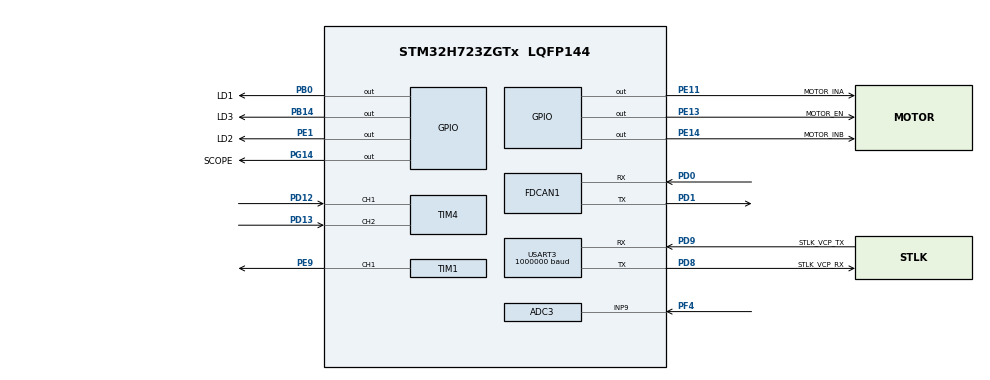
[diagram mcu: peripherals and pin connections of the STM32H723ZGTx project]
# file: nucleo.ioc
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ADC3.Channel-0\#ChannelRegularConversion=ADC_CHANNEL_9
ADC3.ClockPrescalerADC3=ADC_CLOCK_ASYNC_DIV8
ADC3.NbrOfConversionFlag=1
ADC3.OffsetNumber-0\#ChannelRegularConversion=ADC_OFFSET_NONE
ADC3.OffsetSign-0\#ChannelRegularConversion=ADC3_OFFSET_SIGN_NEGATIVE
ADC3.Rank-0\#ChannelRegularConversion=1
ADC3.SamplingTime-0\#ChannelRegularConversion=ADC3_SAMPLETIME_92CYCLES_5
CORTEX_M7.CPU_ICache=Enabled
CORTEX_M7.default_mode_Activation=1
FDCAN1.AutoRetransmission=ENABLE
FDCAN1.CalculateBaudRateNominal=1000000
FDCAN1.CalculateTimeBitNominal=1000
FDCAN1.CalculateTimeQuantumNominal=38.46153846153846
FDCAN1.Mode=FDCAN_MODE_NORMAL
FDCAN1.NominalPrescaler=5
FDCAN1.NominalSyncJumpWidth=5
FDCAN1.NominalTimeSeg1=20
FDCAN1.NominalTimeSeg2=5
FDCAN1.RxFifo0ElmtsNbr=16
FDCAN1.StdFiltersNbr=1
FDCAN1.TxFifoQueueElmtsNbr=16
FREERTOS.Tasks01=init,24,512,task_init,Default,NULL,Dynamic,NULL,NULL
FREERTOS.configCHECK_FOR_STACK_OVERFLOW=2
FREERTOS.configTOTAL_HEAP_SIZE=49152
FREERTOS.configUSE_NEWLIB_REENTRANT=1
Mcu.Family=STM32H7
Mcu.Name=STM32H723ZGTx
Mcu.Package=LQFP144
NVIC.FDCAN1_IT0_IRQn=true\:6\:0\:true\:false\:true\:true\:true\:true\:true
NVIC.PriorityGroup=NVIC_PRIORITYGROUP_4
NVIC.TIM17_IRQn=true\:15\:0\:false\:false\:true\:false\:false\:true\:true
NVIC.TIM6_DAC_IRQn=true\:4\:0\:true\:false\:true\:false\:true\:true\:true
NVIC.TimeBase=TIM17_IRQn
NVIC.TimeBaseIP=TIM17
NVIC.USART3_IRQn=true\:6\:0\:true\:false\:true\:true\:true\:true\:true
PA13(JTMS/SWDIO).GPIO_Label=SWDIO
PA13(JTMS/SWDIO).Mode=Serial_Wire
PA13(JTMS/SWDIO).Signal=DEBUG_JTMS-SWDIO
PA14(JTCK/SWCLK).GPIO_Label=SWCLK
PA14(JTCK/SWCLK).Mode=Serial_Wire
PA14(JTCK/SWCLK).Signal=DEBUG_JTCK-SWCLK
PB0.GPIO_Label=LD1
PB0.Signal=GPIO_Output
PB14.GPIO_Label=LD3
PB14.Signal=GPIO_Output
PC14-OSC32_IN.Signal=RCC_OSC32_IN
PC15-OSC32_OUT.Signal=RCC_OSC32_OUT
PD0.Mode=FDCAN_Activate
PD0.Signal=FDCAN1_RX
PD1.Mode=FDCAN_Activate
PD1.Signal=FDCAN1_TX
PD12.GPIO_PuPd=GPIO_PULLUP
PD12.Signal=S_TIM4_CH1
PD13.GPIO_PuPd=GPIO_PULLUP
PD13.Signal=S_TIM4_CH2
PD8.GPIO_Label=STLK_VCP_RX
PD8.Mode=Asynchronous
PD8.Signal=USART3_TX
PD9.GPIO_Label=STLK_VCP_TX
PD9.Mode=Asynchronous
PD9.Signal=USART3_RX
PE1.GPIO_Label=LD2
PE1.Signal=GPIO_Output
PE11.GPIO_Label=MOTOR_INA
PE11.Signal=GPIO_Output
PE13.GPIO_Label=MOTOR_EN
PE13.GPIO_ModeDefaultOutputPP=GPIO_MODE_OUTPUT_OD
PE13.GPIO_PuPd=GPIO_NOPULL
PE13.PinState=GPIO_PIN_SET
PE13.Signal=GPIO_Output
PE14.GPIO_Label=MOTOR_INB
PE14.Signal=GPIO_Output
PE9.Signal=S_TIM1_CH1
PF4.Mode=IN9-Single-Ended
PF4.Signal=ADC3_INP9
PG14.GPIO_Label=SCOPE
PG14.GPIO_Speed=GPIO_SPEED_FREQ_VERY_HIGH
PG14.Signal=GPIO_Output
PH0-OSC_IN.Mode=HSE-External-Clock-Source
PH0-OSC_IN.Signal=RCC_OSC_IN
ProjectManager.HeapSize=0x200
ProjectManager.StackSize=0x400
ProjectManager.TargetToolchain=CMake
RCC.ADCFreq_Value=96000000
RCC.APB1Freq_Value=130000000
RCC.APB2Freq_Value=130000000
RCC.APB3Freq_Value=130000000
RCC.APB4Freq_Value=130000000
RCC.CortexFreq_Value=520000000
RCC.D1PPRE=RCC_APB3_DIV2
RCC.D2PPRE1=RCC_APB1_DIV2
RCC.D2PPRE2=RCC_APB2_DIV2
RCC.D3PPRE=RCC_APB4_DIV2
RCC.DIVM1=1
RCC.DIVM2=1
RCC.DIVN1=104
RCC.DIVN2=96
RCC.DIVP1=1
RCC.DIVP2=5
RCC.DIVQ1=4
RCC.DIVQ2=5
RCC.HCLKFreq_Value=260000000
RCC.HPRE=RCC_HCLK_DIV2
RCC.HSE_VALUE=5000000
RCC.PLLFRACN=0
RCC.PLLSourceVirtual=RCC_PLLSOURCE_HSE
RCC.SYSCLKFreq_VALUE=520000000
RCC.SYSCLKSource=RCC_SYSCLKSOURCE_PLLCLK
RCC.USBCLockSelection=RCC_USBCLKSOURCE_HSI48
RCC.USBFreq_Value=48000000
SH.S_TIM1_CH1.0=TIM1_CH1,PWM Generation1 CH1
SH.S_TIM4_CH1.0=TIM4_CH1,Encoder_Interface
SH.S_TIM4_CH2.0=TIM4_CH2,Encoder_Interface
TIM1.AutoReloadPreload=TIM_AUTORELOAD_PRELOAD_ENABLE
TIM1.Channel-PWM\ Generation1\ CH1=TIM_CHANNEL_1
TIM1.Period=12999
TIM4.EncoderMode=TIM_ENCODERMODE_TI12
TIM4.IC1Filter=6
TIM4.IC1Polarity=TIM_ICPOLARITY_FALLING
TIM4.IC2Filter=6
TIM6.AutoReloadPreload=TIM_AUTORELOAD_PRELOAD_ENABLE
TIM6.Period=999
TIM6.Prescaler=259
USART3.BaudRate=1000000
USART3.VirtualMode-Asynchronous=VM_ASYNC
VP_FREERTOS_VS_CMSIS_V2.Mode=CMSIS_V2
VP_MEMORYMAP_VS_MEMORYMAP.Mode=CurAppReg
VP_SYS_VS_tim17.Mode=TIM17
VP_TIM1_VS_ClockSourceINT.Mode=Internal
VP_TIM6_VS_ClockSourceINT.Mode=Enable_Timer
board=NUCLEO-H723ZG

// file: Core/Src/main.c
/* USER CODE BEGIN Header */
/**
  ******************************************************************************
  * @file           : main.c
  * @brief          : Main program body
  ******************************************************************************
  * @attention
  *
  * Copyright (c) 2026 STMicroelectronics.
  * All rights reserved.
  *
  * This software is licensed under terms that can be found in the LICENSE file
  * in the root directory of this software component.
  * If no LICENSE file comes with this software, it is provided AS-IS.
  *
  ******************************************************************************
  */
/* USER CODE END Header */
#include "main.h"
#include "FreeRTOS.h"
#include "cmsis_os2.h"
#include "adc.h"
#include "fdcan.h"
#include "tim.h"
#include "usart.h"
#include "gpio.h"

/* USER CODE BEGIN Includes */
#include <stdio.h>
#include "version.h"
/* USER CODE END Includes */

void SystemClock_Config(void);
static void MPU_Config(void);
void MX_FREERTOS_Init(void);

int main(void)
{

  /* MPU Configuration--------------------------------------------------------*/
  MPU_Config();

  /* Enable the CPU Cache */

  /* Enable I-Cache---------------------------------------------------------*/
  SCB_EnableICache();

  /* MCU Configuration--------------------------------------------------------*/

  /* Reset of all peripherals, Initializes the Flash interface and the Systick. */
  HAL_Init();

  /* Configure the system clock */
  SystemClock_Config();

  /* Initialize all configured peripherals */
  MX_GPIO_Init();
  MX_TIM6_Init();
  MX_USART3_UART_Init();
  MX_FDCAN1_Init();
  MX_TIM1_Init();
  MX_TIM4_Init();
  MX_ADC3_Init();
  /* USER CODE BEGIN 2 */
  printf("| ---- BOOT %s (%s) %s ---- |\r\n", FW_VERSION_STR, FW_GIT_DESCRIBE, FW_BUILD_TYPE);
  /* USER CODE END 2 */

  /* Init scheduler */
  osKernelInitialize();  /* Call init function for freertos objects (in cmsis_os2.c) */
  MX_FREERTOS_Init();

  /* Start scheduler */
  osKernelStart();

  /* We should never get here as control is now taken by the scheduler */

  /* Infinite loop */
  while (1)
  {

  }
}

void SystemClock_Config(void)
{
  RCC_OscInitTypeDef RCC_OscInitStruct = {0};
  RCC_ClkInitTypeDef RCC_ClkInitStruct = {0};

  /** Supply configuration update enable
  */
  HAL_PWREx_ConfigSupply(PWR_LDO_SUPPLY);

  /** Configure the main internal regulator output voltage
  */
  __HAL_PWR_VOLTAGESCALING_CONFIG(PWR_REGULATOR_VOLTAGE_SCALE0);

  while(!__HAL_PWR_GET_FLAG(PWR_FLAG_VOSRDY)) {}

  /** Initializes the RCC Oscillators according to the specified parameters
  * in the RCC_OscInitTypeDef structure.
  */
  RCC_OscInitStruct.OscillatorType = RCC_OSCILLATORTYPE_HSE;
  RCC_OscInitStruct.HSEState = RCC_HSE_BYPASS;
  RCC_OscInitStruct.PLL.PLLState = RCC_PLL_ON;
  RCC_OscInitStruct.PLL.PLLSource = RCC_PLLSOURCE_HSE;
  RCC_OscInitStruct.PLL.PLLM = 1;
  RCC_OscInitStruct.PLL.PLLN = 104;
  RCC_OscInitStruct.PLL.PLLP = 1;
  RCC_OscInitStruct.PLL.PLLQ = 4;
  RCC_OscInitStruct.PLL.PLLR = 2;
  RCC_OscInitStruct.PLL.PLLRGE = RCC_PLL1VCIRANGE_2;
  RCC_OscInitStruct.PLL.PLLVCOSEL = RCC_PLL1VCOWIDE;
  RCC_OscInitStruct.PLL.PLLFRACN = 0;
  if (HAL_RCC_OscConfig(&RCC_OscInitStruct) != HAL_OK)
  {
    Error_Handler();
  }

  /** Initializes the CPU, AHB and APB buses clocks
  */
  RCC_ClkInitStruct.ClockType = RCC_CLOCKTYPE_HCLK|RCC_CLOCKTYPE_SYSCLK
                              |RCC_CLOCKTYPE_PCLK1|RCC_CLOCKTYPE_PCLK2
                              |RCC_CLOCKTYPE_D3PCLK1|RCC_CLOCKTYPE_D1PCLK1;
  RCC_ClkInitStruct.SYSCLKSource = RCC_SYSCLKSOURCE_PLLCLK;
  RCC_ClkInitStruct.SYSCLKDivider = RCC_SYSCLK_DIV1;
  RCC_ClkInitStruct.AHBCLKDivider = RCC_HCLK_DIV2;
  RCC_ClkInitStruct.APB3CLKDivider = RCC_APB3_DIV2;
  RCC_ClkInitStruct.APB1CLKDivider = RCC_APB1_DIV2;
  RCC_ClkInitStruct.APB2CLKDivider = RCC_APB2_DIV2;
  RCC_ClkInitStruct.APB4CLKDivider = RCC_APB4_DIV2;

  if (HAL_RCC_ClockConfig(&RCC_ClkInitStruct, FLASH_LATENCY_3) != HAL_OK)
  {
    Error_Handler();
  }
}

 /* MPU Configuration */

void MPU_Config(void)
{
  MPU_Region_InitTypeDef MPU_InitStruct = {0};

  /* Disables the MPU */
  HAL_MPU_Disable();

  /** Initializes and configures the Region and the memory to be protected
  */
  MPU_InitStruct.Enable = MPU_REGION_ENABLE;
  MPU_InitStruct.Number = MPU_REGION_NUMBER0;
  MPU_InitStruct.BaseAddress = 0x0;
  MPU_InitStruct.Size = MPU_REGION_SIZE_4GB;
  MPU_InitStruct.SubRegionDisable = 0x87;
  MPU_InitStruct.TypeExtField = MPU_TEX_LEVEL0;
  MPU_InitStruct.AccessPermission = MPU_REGION_NO_ACCESS;
  MPU_InitStruct.DisableExec = MPU_INSTRUCTION_ACCESS_DISABLE;
  MPU_InitStruct.IsShareable = MPU_ACCESS_SHAREABLE;
  MPU_InitStruct.IsCacheable = MPU_ACCESS_NOT_CACHEABLE;
  MPU_InitStruct.IsBufferable = MPU_ACCESS_NOT_BUFFERABLE;

  HAL_MPU_ConfigRegion(&MPU_InitStruct);
  /* Enables the MPU */
  HAL_MPU_Enable(MPU_PRIVILEGED_DEFAULT);

}

void HAL_TIM_PeriodElapsedCallback(TIM_HandleTypeDef *htim)
{
  if (htim->Instance == TIM17)
  {
    HAL_IncTick();
  }
}

void Error_Handler(void)
{
  __disable_irq();
  while (1)
  {
  }
}

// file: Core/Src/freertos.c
/* USER CODE BEGIN Header */
/**
  ******************************************************************************
  * File Name          : freertos.c
  * Description        : Code for freertos applications
  ******************************************************************************
  * @attention
  *
  * Copyright (c) 2026 STMicroelectronics.
  * All rights reserved.
  *
  * This software is licensed under terms that can be found in the LICENSE file
  * in the root directory of this software component.
  * If no LICENSE file comes with this software, it is provided AS-IS.
  *
  ******************************************************************************
  */
/* USER CODE END Header */

#include "FreeRTOS.h"
#include "task.h"
#include "main.h"
#include "FreeRTOS.h"
#include "cmsis_os2.h"

/* USER CODE BEGIN Includes */
#include "task_init.h"
/* USER CODE END Includes */

/* Definitions for init */
osThreadId_t initHandle;
const osThreadAttr_t init_attributes = {
  .name = "init",
  .stack_size = 512 * 4,
  .priority = (osPriority_t) osPriorityNormal,
};

void task_init(void *argument);

void MX_FREERTOS_Init(void); /* (MISRA C 2004 rule 8.1) */

/* Hook prototypes */
void vApplicationStackOverflowHook(xTaskHandle xTask, char *pcTaskName);

/* USER CODE BEGIN 4 */
void vApplicationStackOverflowHook(xTaskHandle xTask, char *pcTaskName)
{
  /* A task overran its stack (configCHECK_FOR_STACK_OVERFLOW = 2). Memory
   * is already corrupt, so don't log: LD3 on and halt for the debugger.
   * pcTaskName says which task. */
  (void)xTask;
  (void)pcTaskName;
  __disable_irq();
  HAL_GPIO_WritePin(LD3_GPIO_Port, LD3_Pin, GPIO_PIN_SET);
  for (;;) {
  }
}
/* USER CODE END 4 */

void MX_FREERTOS_Init(void) {

  /* Create the thread(s) */
  /* creation of init */
  initHandle = osThreadNew(task_init, NULL, &init_attributes);

  /* USER CODE BEGIN RTOS_THREADS */
  /* tasks are created by the init task (app/task_init.c) */
  /* USER CODE END RTOS_THREADS */

}

void task_init(void *argument)
{
  /* USER CODE BEGIN task_init */
  task_init_run(argument);
  /* Infinite loop */
  for(;;)
  {
    osDelay(1);
  }
  /* USER CODE END task_init */
}
